# nrf5340_network register map
Vendor: Nordic Semiconductor; Series: nrf53; File version: 1
CPU: CM33 r0p4, little endian, MPU, no FPU, 3 interrupt priority bits, 30 interrupts
Registers are 32-bit, read-write, reset 0x0 unless marked. A register's access mark holds for its fields unless they carry their own. Offsets are from the block's base; [hi:lo] are bit positions; lines under a group give offsets from that group; {n}, {i} and the like mark numbered series; 'fields as' and 'values as' point back to an identical list.

## VMC_NS — Volatile Memory controller
Base 0x41081000
{0x600+0x10*i} RAM[{i}] (i=0..3) group — Unspecified
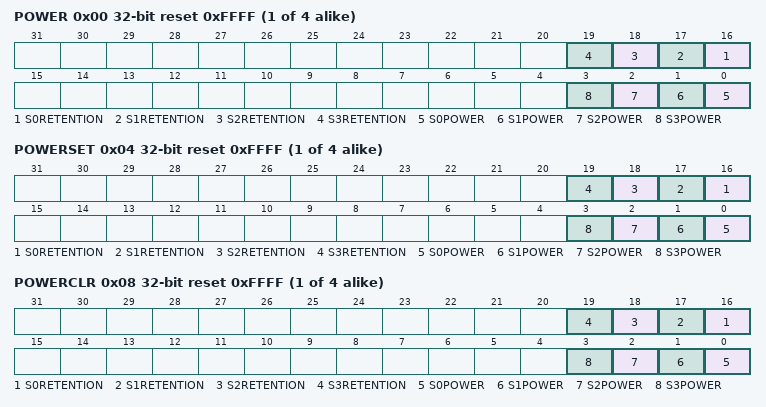
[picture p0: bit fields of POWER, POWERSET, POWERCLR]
  0x00 POWER reset 0xFFFF — Description cluster: RAM[n] power control register
    [all] fields
      0=Off; 1=On
    [n+16] S{n}RETENTION (n=0..3) — Keep retention on RAM section S{n} of RAM[n] when RAM section is switched off
    [n] S{n}POWER (n=0..3) — Keep RAM section S{n} of RAM[n] on or off in System ON mode
  0x04 POWERSET reset 0xFFFF — Description cluster: RAM[n] power control set register
    [all] fields
      1=On
    [n+16] S{n}RETENTION (n=0..3) — Keep retention on RAM section S{n} of RAM[n] when RAM section is switched off
    [n] S{n}POWER (n=0..3) — Keep RAM section S{n} of RAM[n] on or off in System ON mode
  0x08 POWERCLR reset 0xFFFF — Description cluster: RAM[n] power control clear register
    [all] fields
      1=Off
    [n+16] S{n}RETENTION (n=0..3) — Keep retention on RAM section S{n} of RAM[n] when RAM section is switched off
    [n] S{n}POWER (n=0..3) — Keep RAM section S{n} of RAM[n] on or off in System ON mode

## P0_NS — GPIO Port 0
Base 0x418C0500
Same registers: P1_NS 0x418C0800
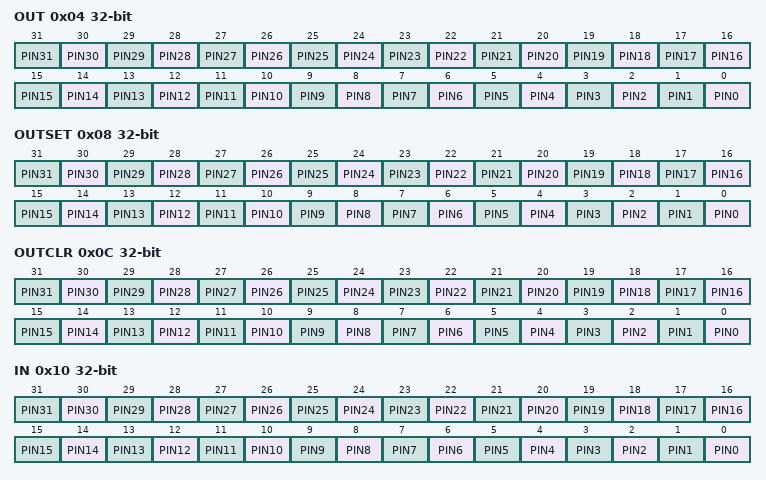
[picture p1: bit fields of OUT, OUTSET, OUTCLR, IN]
0x04 OUT — Write GPIO port
  [all] fields
    0=Low (Pin driver is low); 1=High (Pin driver is high)
  [n] PIN{n} (n=0..31)
0x08 OUTSET write-1-sets — Set individual bits in GPIO port
  [all] fields
    on read: 0=Low (Read: pin driver is low); 1=High (Read: pin driver is high) | on write: 1=Set (Write: writing a '1' sets the pin high; writing a '0' has no effect)
  [n] PIN{n} (n=0..31)
0x0C OUTCLR write-1-clears — Clear individual bits in GPIO port
  [all] fields
    on read: 0=Low (Read: pin driver is low); 1=High (Read: pin driver is high) | on write: 1=Clear (Write: writing a '1' sets the pin low; writing a '0' has no effect)
  [n] PIN{n} (n=0..31)
0x10 IN ro — Read GPIO port
  [all] fields
    0=Low (Pin input is low); 1=High (Pin input is high)
  [n] PIN{n} (n=0..31)
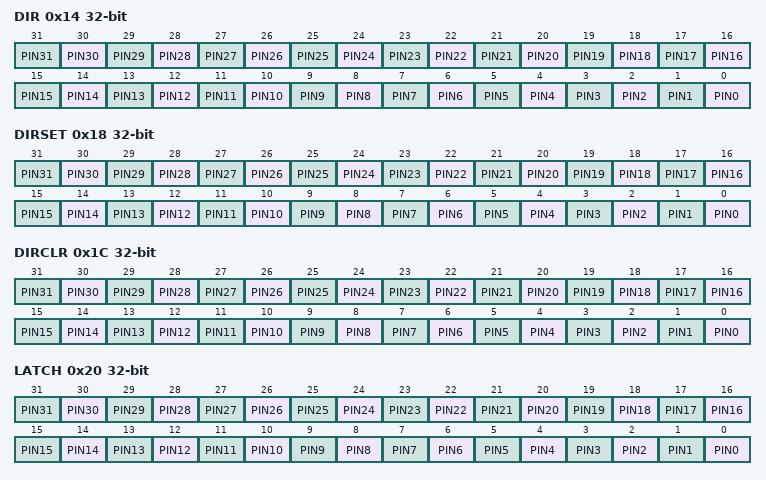
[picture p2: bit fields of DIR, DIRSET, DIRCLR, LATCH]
0x14 DIR — Direction of GPIO pins
  [all] fields
    0=Input (Pin set as input); 1=Output (Pin set as output)
  [n] PIN{n} (n=0..31)
0x18 DIRSET write-1-sets
  [all] fields
    on read: 0=Input (Read: pin set as input); 1=Output (Read: pin set as output) | on write: 1=Set (Write: writing a '1' sets pin to output; writing a '0' has no effect)
  [n] PIN{n} (n=0..31) — Set as output pin {n}
0x1C DIRCLR write-1-clears — DIR clear register
  [all] fields
    on read: 0=Input (Read: pin set as input); 1=Output (Read: pin set as output) | on write: 1=Clear (Write: writing a '1' sets pin to input; writing a '0' has no effect)
  [n] PIN{n} (n=0..31) — Set as input pin {n}
0x20 LATCH — Latch register indicating what GPIO pins that have met the criteria set in the PIN_CNF[n].SENSE registers
  [all] fields
    0=NotLatched (Criteria has not been met); 1=Latched (Criteria has been met)
  [n] PIN{n} (n=0..31) — Status on whether PIN[{n}] has met criteria set in PIN_CNF[{n}].SENSE register. Write '1' to clear.
0x24 DETECTMODE — Select between default DETECT signal behavior and LDETECT mode
  [0] DETECTMODE
    0=Default (DETECT directly connected to PIN DETECT signals); 1=LDETECT (Use the latched LDETECT behavior)
0x28 DETECTMODE_SEC — Select between default DETECT signal behavior and LDETECT mode
  fields as DETECTMODE
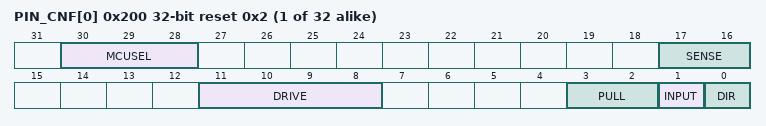
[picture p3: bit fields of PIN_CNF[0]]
{0x200+4i} PIN_CNF[{i}] (i=0..31) reset 0x2 — Description collection: Configuration of GPIO pins
  [30:28] MCUSEL — Select which MCU/Subsystem controls this pin Note: this field is only accessible from secure code.
    0=AppMCU (Application MCU); 1=NetworkMCU; 3=Peripheral with dedicated pins; 7=TND (Trace and Debug Subsystem)
  [17:16] SENSE — Pin sensing mechanism
    0=Disabled; 2=High (Sense for high level); 3=Low (Sense for low level)
  [11:8] DRIVE — Drive configuration
    0=S0S1 (Standard '0', standard '1'); 1=H0S1 (High drive '0', standard '1'); 2=S0H1 (Standard '0', high drive '1'); 3=H0H1 (High drive '0', high 'drive '1''); 4=D0S1 (Disconnect '0', standard '1' (normally used for wired-or connections)); 5=D0H1 (Disconnect '0', high drive '1' (normally used for wired-or connections)); 6=S0D1 (Standard '0', disconnect '1' (normally used for wired-and connections)); 7=H0D1 (High drive '0', disconnect '1' (normally used for wired-and connections)); 11=E0E1 (Extra high drive '0', extra high drive '1')
  [3:2] PULL — Pull configuration
    0=Disabled (No pull); 1=Pull down on pin; 3=Pull up on pin
  [1] INPUT — Connect or disconnect input buffer
    0=Connect input buffer; 1=Disconnect input buffer
  [0] DIR — Pin direction. Same physical register as DIR register
    0=Input (Configure pin as an input pin); 1=Output (Configure pin as an output pin)
